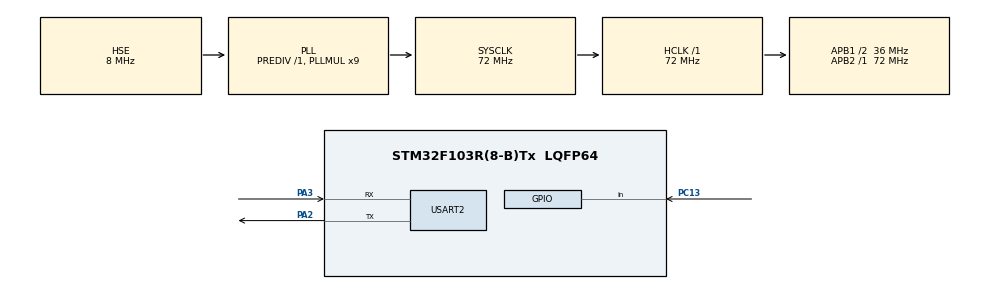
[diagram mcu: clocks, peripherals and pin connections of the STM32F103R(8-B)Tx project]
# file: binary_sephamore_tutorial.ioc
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FREERTOS.BinarySemaphores01=bin_semaphore,Dynamic,NULL
FREERTOS.Tasks01=norm_task,24,128,start_norm_task,Default,NULL,Dynamic,NULL,NULL;high_task,40,128,start_high_task,Default,NULL,Dynamic,NULL,NULL;low_task,16,128,start_low_task,Default,NULL,Dynamic,NULL,NULL
Mcu.Family=STM32F1
Mcu.Name=STM32F103R(8-B)Tx
Mcu.Package=LQFP64
NVIC.PriorityGroup=NVIC_PRIORITYGROUP_4
NVIC.TIM1_UP_IRQn=true\:0\:0\:false\:false\:true\:false\:false\:true
NVIC.TimeBase=TIM1_UP_IRQn
NVIC.TimeBaseIP=TIM1
PA2.Mode=Asynchronous
PA2.Signal=USART2_TX
PA3.Mode=Asynchronous
PA3.Signal=USART2_RX
PC13-TAMPER-RTC.Signal=GPIO_Input
PD0-OSC_IN.Mode=HSE-External-Oscillator
PD0-OSC_IN.Signal=RCC_OSC_IN
PD1-OSC_OUT.Mode=HSE-External-Oscillator
PD1-OSC_OUT.Signal=RCC_OSC_OUT
ProjectManager.HeapSize=0x200
ProjectManager.StackSize=0x400
ProjectManager.TargetToolchain=MDK-ARM V5.27
RCC.AHBFreq_Value=72000000
RCC.APB1CLKDivider=RCC_HCLK_DIV2
RCC.APB1Freq_Value=36000000
RCC.APB1TimFreq_Value=72000000
RCC.APB2Freq_Value=72000000
RCC.APB2TimFreq_Value=72000000
RCC.HCLKFreq_Value=72000000
RCC.PLLMUL=RCC_PLL_MUL9
RCC.PLLSourceVirtual=RCC_PLLSOURCE_HSE
RCC.RTCClockSelection=RCC_RTCCLKSOURCE_LSE
RCC.SYSCLKFreq_VALUE=72000000
RCC.SYSCLKSource=RCC_SYSCLKSOURCE_PLLCLK
RCC.USBFreq_Value=72000000
USART2.VirtualMode=VM_ASYNC
VP_FREERTOS_VS_CMSIS_V2.Mode=CMSIS_V2
VP_SYS_VS_ND.Mode=No_Debug
VP_SYS_VS_tim1.Mode=TIM1
board=NUCLEO-F103RB

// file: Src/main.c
/* USER CODE BEGIN Header */
/**
  ******************************************************************************
  * @file           : main.c
  * @brief          : Main program body
  ******************************************************************************
  * @attention
  *
  * <h2><center>&copy; Copyright (c) 2020 STMicroelectronics.
  * All rights reserved.</center></h2>
  *
  * This software component is licensed by ST under Ultimate Liberty license
  * SLA0044, the "License"; You may not use this file except in compliance with
  * the License. You may obtain a copy of the License at:
  *                             www.st.com/SLA0044
  *
  ******************************************************************************
  */
/* USER CODE END Header */

#include "main.h"
#include "cmsis_os.h"

/* USER CODE BEGIN Includes */
#include "string.h"
/* USER CODE END Includes */

UART_HandleTypeDef huart2;

/* Definitions for norm_task */
osThreadId_t norm_taskHandle;
const osThreadAttr_t norm_task_attributes = {
  .name = "norm_task",
  .priority = (osPriority_t) osPriorityNormal,
  .stack_size = 128
};
/* Definitions for high_task */
osThreadId_t high_taskHandle;
const osThreadAttr_t high_task_attributes = {
  .name = "high_task",
  .priority = (osPriority_t) osPriorityHigh,
  .stack_size = 128
};
/* Definitions for low_task */
osThreadId_t low_taskHandle;
const osThreadAttr_t low_task_attributes = {
  .name = "low_task",
  .priority = (osPriority_t) osPriorityBelowNormal,
  .stack_size = 128
};
/* Definitions for bin_semaphore */
osSemaphoreId_t bin_semaphoreHandle;
const osSemaphoreAttr_t bin_semaphore_attributes = {
  .name = "bin_semaphore"
};

void SystemClock_Config(void);
static void MX_GPIO_Init(void);
static void MX_USART2_UART_Init(void);
void start_norm_task(void *argument);
void start_high_task(void *argument);
void start_low_task(void *argument);

int main(void)
{

  /* MCU Configuration--------------------------------------------------------*/

  /* Reset of all peripherals, Initializes the Flash interface and the Systick. */
  HAL_Init();

  /* Configure the system clock */
  SystemClock_Config();

  /* Initialize all configured peripherals */
  MX_GPIO_Init();
  MX_USART2_UART_Init();
  /* Init scheduler */
  osKernelInitialize();

  /* Create the semaphores(s) */
  /* creation of bin_semaphore */
  bin_semaphoreHandle = osSemaphoreNew(1, 1, &bin_semaphore_attributes);

  /* Create the thread(s) */
  /* creation of norm_task */
  norm_taskHandle = osThreadNew(start_norm_task, NULL, &norm_task_attributes);

  /* creation of high_task */
  high_taskHandle = osThreadNew(start_high_task, NULL, &high_task_attributes);

  /* creation of low_task */
  low_taskHandle = osThreadNew(start_low_task, NULL, &low_task_attributes);

  /* Start scheduler */
  osKernelStart();

  /* We should never get here as control is now taken by the scheduler */

  /* Infinite loop */
  while (1)
  {

  }
}

void SystemClock_Config(void)
{
  RCC_OscInitTypeDef RCC_OscInitStruct = {0};
  RCC_ClkInitTypeDef RCC_ClkInitStruct = {0};

  /** Initializes the CPU, AHB and APB busses clocks
  */
  RCC_OscInitStruct.OscillatorType = RCC_OSCILLATORTYPE_HSE;
  RCC_OscInitStruct.HSEState = RCC_HSE_ON;
  RCC_OscInitStruct.HSEPredivValue = RCC_HSE_PREDIV_DIV1;
  RCC_OscInitStruct.HSIState = RCC_HSI_ON;
  RCC_OscInitStruct.PLL.PLLState = RCC_PLL_ON;
  RCC_OscInitStruct.PLL.PLLSource = RCC_PLLSOURCE_HSE;
  RCC_OscInitStruct.PLL.PLLMUL = RCC_PLL_MUL9;
  if (HAL_RCC_OscConfig(&RCC_OscInitStruct) != HAL_OK)
  {
    Error_Handler();
  }
  /** Initializes the CPU, AHB and APB busses clocks
  */
  RCC_ClkInitStruct.ClockType = RCC_CLOCKTYPE_HCLK|RCC_CLOCKTYPE_SYSCLK
                              |RCC_CLOCKTYPE_PCLK1|RCC_CLOCKTYPE_PCLK2;
  RCC_ClkInitStruct.SYSCLKSource = RCC_SYSCLKSOURCE_PLLCLK;
  RCC_ClkInitStruct.AHBCLKDivider = RCC_SYSCLK_DIV1;
  RCC_ClkInitStruct.APB1CLKDivider = RCC_HCLK_DIV2;
  RCC_ClkInitStruct.APB2CLKDivider = RCC_HCLK_DIV1;

  if (HAL_RCC_ClockConfig(&RCC_ClkInitStruct, FLASH_LATENCY_2) != HAL_OK)
  {
    Error_Handler();
  }
}

static void MX_USART2_UART_Init(void)
{

  huart2.Instance = USART2;
  huart2.Init.BaudRate = 115200;
  huart2.Init.WordLength = UART_WORDLENGTH_8B;
  huart2.Init.StopBits = UART_STOPBITS_1;
  huart2.Init.Parity = UART_PARITY_NONE;
  huart2.Init.Mode = UART_MODE_TX_RX;
  huart2.Init.HwFlowCtl = UART_HWCONTROL_NONE;
  huart2.Init.OverSampling = UART_OVERSAMPLING_16;
  if (HAL_UART_Init(&huart2) != HAL_OK)
  {
    Error_Handler();
  }

}

static void MX_GPIO_Init(void)
{
  GPIO_InitTypeDef GPIO_InitStruct = {0};

  /* GPIO Ports Clock Enable */
  __HAL_RCC_GPIOC_CLK_ENABLE();
  __HAL_RCC_GPIOD_CLK_ENABLE();
  __HAL_RCC_GPIOA_CLK_ENABLE();

  /*Configure GPIO pin : PC13 */
  GPIO_InitStruct.Pin = GPIO_PIN_13;
  GPIO_InitStruct.Mode = GPIO_MODE_INPUT;
  GPIO_InitStruct.Pull = GPIO_NOPULL;
  HAL_GPIO_Init(GPIOC, &GPIO_InitStruct);

}

void start_norm_task(void *argument)
{
  /* USER CODE BEGIN 5 */
  /* Infinite loop */
  for(;;)
  {
		char * entry_str = "Running Normal task.\r\n";
		HAL_UART_Transmit(&huart2, (uint8_t *) entry_str, strlen(entry_str), 100);

		char * leave_str = "Leaving Normal task.\r\n\n";
		HAL_UART_Transmit(&huart2, (uint8_t *) leave_str, strlen(leave_str), 100);

    osDelay(500);
  }
  /* USER CODE END 5 */
}

void start_high_task(void *argument)
{
  /* USER CODE BEGIN start_high_task */
  /* Infinite loop */
  for(;;)
  {
		char * entry_str = "Running High task.\r\n";
		HAL_UART_Transmit(&huart2, (uint8_t *) entry_str, strlen(entry_str), 100);

		osSemaphoreAcquire(bin_semaphoreHandle, osWaitForever);
		char * semaphore_str = "Semaphore acquired by High!\r\n";
		HAL_UART_Transmit(&huart2, (uint8_t *) semaphore_str, strlen(semaphore_str), 100);

		char * leave_str = "Leaving High task and releasing semaphore.\r\n\n";
		HAL_UART_Transmit(&huart2, (uint8_t *) leave_str, strlen(leave_str), 100);

	  osSemaphoreRelease(bin_semaphoreHandle);
    osDelay(500);
  }
  /* USER CODE END start_high_task */
}

void start_low_task(void *argument)
{
  /* USER CODE BEGIN start_low_task */
  /* Infinite loop */
  for(;;)
  {
		char * entry_str = "Running Low task.\r\n";
		HAL_UART_Transmit(&huart2, (uint8_t *) entry_str, strlen(entry_str), 100);

		osSemaphoreAcquire(bin_semaphoreHandle, osWaitForever);
		char * semaphore_str = "Semaphore acquired by Low!\r\n";
		HAL_UART_Transmit(&huart2, (uint8_t *) semaphore_str, strlen(semaphore_str), 100);

		while(HAL_GPIO_ReadPin(GPIOC, GPIO_PIN_13));

		char * leave_str = "Leaving Low task.\r\n\n";
		HAL_UART_Transmit(&huart2, (uint8_t *) leave_str, strlen(leave_str), 100);

		osSemaphoreRelease(bin_semaphoreHandle);
    osDelay(500);
  }
  /* USER CODE END start_low_task */
}

void HAL_TIM_PeriodElapsedCallback(TIM_HandleTypeDef *htim)
{
  if (htim->Instance == TIM1) {
    HAL_IncTick();
  }
}

void Error_Handler(void)
{
}

/************************ (C) COPYRIGHT STMicroelectronics *****END OF FILE****/
